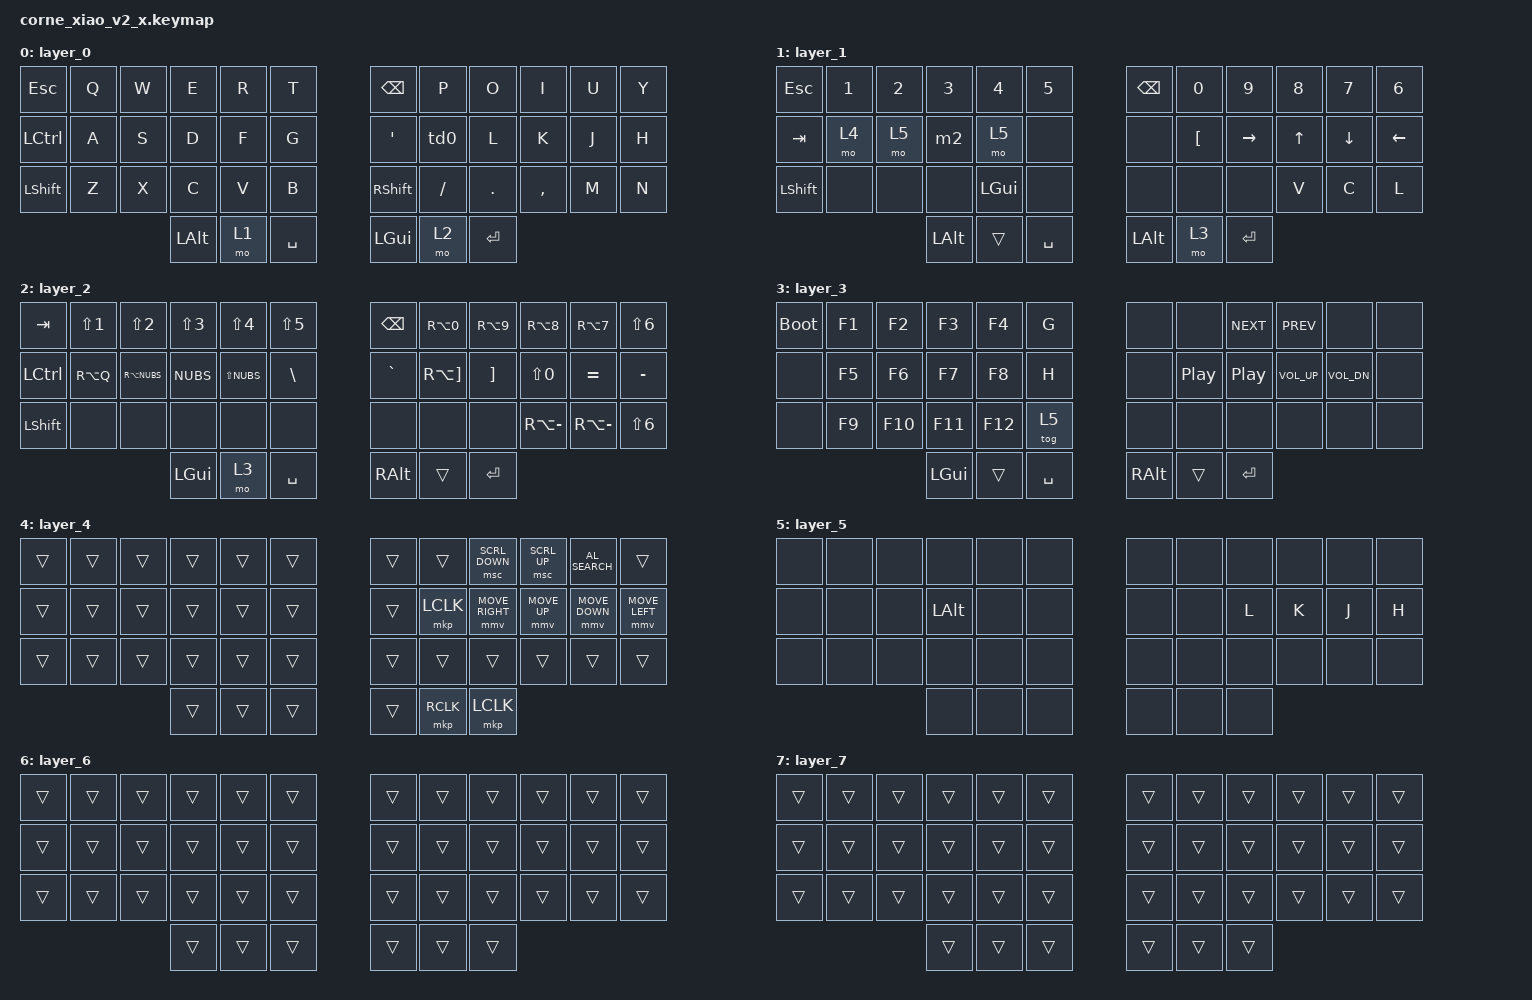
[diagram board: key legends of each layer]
#include <behaviors.dtsi>
#include <dt-bindings/zmk/keys.h>
#include <dt-bindings/zmk/pointing.h>

/ {
    behaviors {
        td0: tap_dance_0 {
            compatible = "zmk,behavior-tap-dance";
            #binding-cells = <0>;
            tapping-term-ms = <150>;
            bindings = <&kp SEMI>, <&kp LBKT>;
        };
    };

    macros {
        /* Vial M0: GUI+Shift+S */
        m0: macro_0 {
            compatible = "zmk,behavior-macro";
            #binding-cells = <0>;
            bindings = <&kp LG(LS(S))>;
        };

        /* Vial M1: Alt+Space */
        m1: macro_1 {
            compatible = "zmk,behavior-macro";
            #binding-cells = <0>;
            bindings = <&kp LA(SPACE)>;
        };

        /*
         * Vial M2 stores: down(GUI, TAB, GUI, TAB).
         * Interpreted here as two GUI+Tab taps, avoiding stuck modifiers.
         */
        m2: macro_2 {
            compatible = "zmk,behavior-macro";
            #binding-cells = <0>;
            wait-ms = <40>;
            tap-ms = <40>;
            bindings = <&kp LG(TAB)>, <&kp LG(TAB)>;
        };
    };

    keymap {
        compatible = "zmk,keymap";

        layer_0 {
            bindings = <
                &kp ESC    &kp Q      &kp W      &kp E      &kp R      &kp T       &kp BSPC   &kp P      &kp O      &kp I      &kp U      &kp Y
                &kp LCTRL  &kp A      &kp S      &kp D      &kp F      &kp G       &kp SQT    &td0       &kp L      &kp K      &kp J      &kp H
                &kp LSHFT  &kp Z      &kp X      &kp C      &kp V      &kp B       &kp RSHFT  &kp SLASH  &kp DOT    &kp COMMA  &kp M      &kp N
                                      &kp LALT   &mo 1      &kp SPACE              &kp LGUI   &mo 2      &kp ENTER
            >;
        };

        layer_1 {
            bindings = <
                &kp ESC    &kp N1     &kp N2     &kp N3     &kp N4     &kp N5      &kp BSPC   &kp N0     &kp N9     &kp N8     &kp N7     &kp N6
                &kp TAB    &mo 4      &mo 5      &m2        &mo 5      &none        &none      &kp LBKT   &kp RIGHT  &kp UP     &kp DOWN   &kp LEFT
                &kp LSHFT  &none      &none      &none      &kp LGUI   &none        &none      &none      &none      &kp V      &kp C      &kp L
                                      &kp LALT   &trans      &kp SPACE              &kp LALT   &mo 3      &kp ENTER
            >;
        };

        layer_2 {
            bindings = <
                &kp TAB    &kp LS(N1) &kp LS(N2) &kp LS(N3) &kp LS(N4) &kp LS(N5)  &kp BSPC   &kp RA(N0) &kp RA(N9) &kp RA(N8) &kp RA(N7) &kp LS(N6)
                &kp LCTRL  &kp RA(Q)  &kp RA(NUBS)&kp NUBS   &kp LS(NUBS)&kp BSLH   &kp GRAVE  &kp RA(RBKT)&kp RBKT  &kp LS(N0) &kp EQUAL  &kp MINUS
                &kp LSHFT  &none      &none      &none      &none      &none        &none      &none      &none      &kp RA(MINUS)&kp RA(MINUS)&kp LS(N6)
                                      &kp LGUI   &mo 3      &kp SPACE              &kp RALT   &trans      &kp ENTER
            >;
        };

        layer_3 {
            bindings = <
                &bootloader &kp F1    &kp F2     &kp F3     &kp F4     &kp G        &none      &none      &kp C_NEXT &kp C_PREV &none      &none
                &none       &kp F5    &kp F6     &kp F7     &kp F8     &kp H        &none      &kp C_PP   &kp C_PP   &kp C_VOL_UP &kp C_VOL_DN &none
                &none       &kp F9    &kp F10    &kp F11    &kp F12    &tog 5       &none      &none      &none      &none      &none      &none
                                       &kp LGUI  &trans      &kp SPACE              &kp RALT   &trans      &kp ENTER
            >;
        };

        layer_4 {
            bindings = <
                &trans      &trans      &trans      &trans      &trans      &trans       &trans      &trans      &msc SCRL_DOWN &msc SCRL_UP &kp C_AL_SEARCH &trans
                &trans      &trans      &trans      &trans      &trans      &trans       &trans      &mkp LCLK   &mmv MOVE_RIGHT &mmv MOVE_UP &mmv MOVE_DOWN &mmv MOVE_LEFT
                &trans      &trans      &trans      &trans      &trans      &trans       &trans      &trans      &trans      &trans      &trans      &trans
                                        &trans      &trans      &trans                   &trans      &mkp RCLK   &mkp LCLK
            >;
        };

        layer_5 {
            bindings = <
                &none &none &none &none    &none &none     &none &none &none &none &none &none
                &none &none &none &kp LALT &none &none     &none &none &kp L &kp K &kp J &kp H
                &none &none &none &none    &none &none     &none &none &none &none &none &none
                                  &none    &none &none                 &none &none &none
            >;
        };

        layer_6 {
            bindings = <
                &trans &trans &trans &trans &trans &trans   &trans &trans &trans &trans &trans &trans
                &trans &trans &trans &trans &trans &trans   &trans &trans &trans &trans &trans &trans
                &trans &trans &trans &trans &trans &trans   &trans &trans &trans &trans &trans &trans
                                      &trans &trans &trans           &trans &trans &trans
            >;
        };

        layer_7 {
            bindings = <
                &trans &trans &trans &trans &trans &trans   &trans &trans &trans &trans &trans &trans
                &trans &trans &trans &trans &trans &trans   &trans &trans &trans &trans &trans &trans
                &trans &trans &trans &trans &trans &trans   &trans &trans &trans &trans &trans &trans
                                      &trans &trans &trans           &trans &trans &trans
            >;
        };
    };
};
